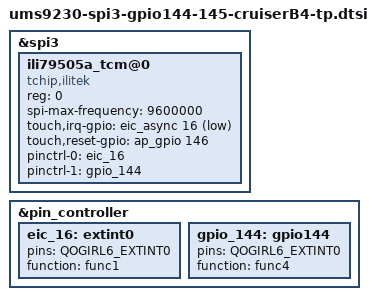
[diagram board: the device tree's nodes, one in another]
// SPDX-License-Identifier: (Licenseref-Unisoc-General-1.0 OR GPL-2.0-only)
/*
* ums9230-spi3-gpio144-145-tp.dtsi - Unisoc platform device
*
* Copyright 2022 Unisoc(Shanghai) Technologies Co.Ltd
*
* Licensed under the Unisoc General Software License, version 1.0 (the
* License);
 * you may not use this file except in compliance with the License.
 * You may obtain a copy of the License at
 * https://www.unisoc.com/en_us/license/UNISOC_GENERAL_LICENSE_V1.0-EN_US
 * Software distributed under the License is distributed on an "AS IS" BASIS,
 * WITHOUT WARRANTIES OF ANY KIND, either express or implied.
* See the Unisoc General Software License, version 1.0 for more details.
*
* Alternatively you can use and distribute this file under the terms of the
 * GNU General Public License version 2, provided that it has to be used
*  (including but not limited to combining, linking) with any other file under
* the GNU General Public License version 2 on platforms that use Unisoc Chips.
*/

&spi3 {
	status = "okay";
	#address-cells = <1>;
	#size-cells = <0>;

	ili79505a_tcm@0 {
		compatible = "tchip,ilitek";
		reg = <0>;
		spi-max-frequency = <9600000>;

		/* ILITEK 79505a */
		// touch,irq-gpio = <&ap_gpio 144 0x2008>;
		touch,irq-gpio = <&eic_async 16 GPIO_ACTIVE_LOW>;
		touch,reset-gpio = <&ap_gpio 146 0x00>;

		pinctrl-names = "eic_16", "gpio_144";
		pinctrl-0 = <&eic_16>;
		pinctrl-1 = <&gpio_144>;
	};
};

&pin_controller {
	eic_16: extint0 {
		pins = "QOGIRL6_EXTINT0";
		function = "func1";
	};

	gpio_144:gpio144 {
		pins = "QOGIRL6_EXTINT0";
		function = "func4";
	};
};
